AUTOSAR XML (schema 00049)
package /ARRoot
  swc implementation LedControlImpl: behavior=LedControlInternalBehaviour
  system signal LedSignalSystem
  can cluster SpeedCANCluster
  ecu instance SpeedECU
    can communication controller CanController
    can communication connector CanCommunicationConnector: comm-controller=CanController
  system SpeedLightSystem
    system mapping SpeedSystemMapping
      data-mappings:
        data-element=SpeedCompositionPrototype.SpeedLightRootSwComposition.WheelSpeedPPort.WheelSpeed, system-signal=WheelSpeedSignal
        data-element=SpeedCompositionPrototype.SpeedLightRootSwComposition.VechicleSpeedPPort.VechicleSpeed, system-signal=VehicleSpeedSignal
        data-element=SpeedCompositionPrototype.SpeedLightRootSwComposition.LedSignalPPort.LedSignal, system-signal=LedSignalSystem
      mapping-constraints:
        component=SpeedLightRootSwComposition.SpeedCompositionPrototype.WheelSpeedSwComponentPrototype, ecu-instance=SpeedECU
        component=SpeedLightRootSwComposition.SpeedCompositionPrototype.VechicleSpeedSwComponentPrototype, ecu-instance=SpeedECU
        component=SpeedLightRootSwComposition.SpeedCompositionPrototype.LedControlComponentPrototype, ecu-instance=SpeedECU
      sw-impl-mappings:
        swc to impl mapping LedControlImplMapping: component-implementation=LedControlImpl, component=SpeedLightRootSwComposition.SpeedCompositionPrototype.LedControlComponentPrototype
        swc to impl mapping VehicleSpeedImplMapping: component-implementation=VehicleSpeedImpl, component=SpeedLightRootSwComposition.SpeedCompositionPrototype.VechicleSpeedSwComponentPrototype
        swc to impl mapping WheelSpeedImplMapping: component-implementation=WheelSpeedImpl, component=SpeedLightRootSwComposition.SpeedCompositionPrototype.WheelSpeedSwComponentPrototype
    root-software-compositions:
      root sw composition prototype SpeedLightRootSwComposition: software-composition=TopLevelComposition
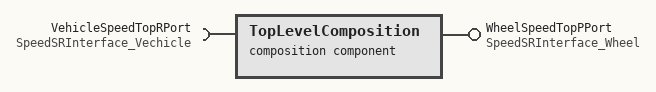
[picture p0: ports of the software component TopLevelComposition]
  composition sw component type TopLevelComposition
    require port VehicleSpeedTopRPort: required-interface=SpeedSRInterface_Vechicle
    provide port WheelSpeedTopPPort: provided-interface=SpeedSRInterface_Wheel
    component SpeedCompositionPrototype: type=SpeedComposition
    delegate VechicleSpeedRPort <-> outer port VehicleSpeedTopRPort
    delegate WheelSpeedRPort <-> outer port WheelSpeedTopPPort
  swc implementation VehicleSpeedImpl: behavior=VechicleSpeedInternalBehaviour
  system signal VehicleSpeedSignal
  swc implementation WheelSpeedImpl: behavior=WheelSpeedInternalBehaviour
  system signal WheelSpeedSignal
